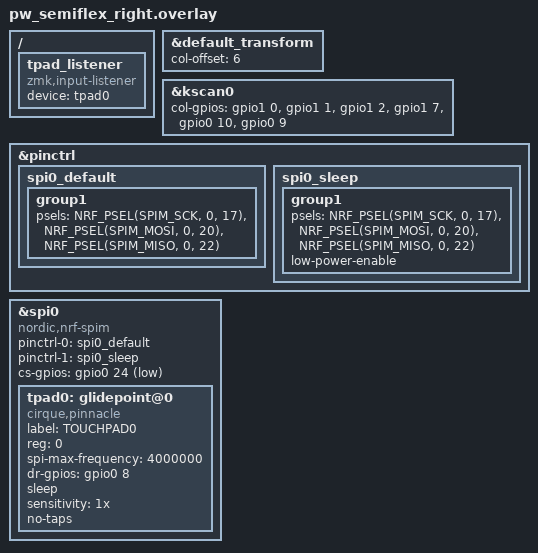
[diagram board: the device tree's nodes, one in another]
#include "pw_semiflex.dtsi"

&default_transform {
    col-offset = <6>;
};

&kscan0 {
    col-gpios
        = <&gpio1 0 GPIO_ACTIVE_HIGH> // Column 6
        , <&gpio1 1 GPIO_ACTIVE_HIGH> // Column 5
        , <&gpio1 2 GPIO_ACTIVE_HIGH> // Column 4
        , <&gpio1 7 GPIO_ACTIVE_HIGH> // Column 3
        , <&gpio0 10 GPIO_ACTIVE_HIGH> // Column 2
        , <&gpio0 9 GPIO_ACTIVE_HIGH> // Column 1
        ;
};

&pinctrl {
    spi0_default: spi0_default {
        group1 {
            psels = <NRF_PSEL(SPIM_SCK, 0, 17)>,
                    <NRF_PSEL(SPIM_MOSI, 0, 20)>,
                    <NRF_PSEL(SPIM_MISO, 0, 22)>;
        };
    };
    spi0_sleep: spi0_sleep {
        group1 {
            psels = <NRF_PSEL(SPIM_SCK, 0, 17)>,
                    <NRF_PSEL(SPIM_MOSI, 0, 20)>,
                    <NRF_PSEL(SPIM_MISO, 0, 22)>;
            low-power-enable;
        };
    };
};

&spi0 {
    compatible = "nordic,nrf-spim";
    status = "okay";

    pinctrl-0 = <&spi0_default>;
    pinctrl-1 = <&spi0_sleep>;
    pinctrl-names = "default", "sleep";
    cs-gpios = <&gpio0 24 GPIO_ACTIVE_LOW>;
    tpad0: glidepoint@0 {
        compatible = "cirque,pinnacle";
        status = "disabled";
        label = "TOUCHPAD0";
        reg = <0>;
        spi-max-frequency = <4000000>;
    };
};
&tpad0 {
    status = "okay";
    dr-gpios = <&gpio0 8 GPIO_ACTIVE_HIGH>;
    sleep;
    sensitivity = "1x";
    no-taps;
};


/ {
  tpad_listener {
    compatible = "zmk,input-listener";
    device = <&tpad0>;
  };
};
